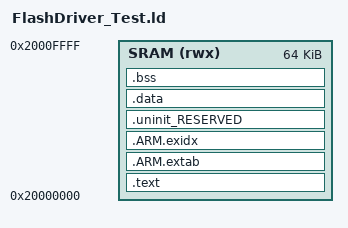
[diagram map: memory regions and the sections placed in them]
/*
 * Linker script for NXP iMXRT SPIFI Flash Driver (Messaged)
*/

__stack_size = 128;								/* stack size */
__cache_size = (16 * 1024);			/* flash image buffer size */
	
MEMORY
{
	  SRAM (rwx) : ORIGIN = 0x20000000, LENGTH = (64 * 1024)
}


__top_SRAM = 0x20000000 + (64 * 1024);

 
GROUP(libcr_semihost.a libcr_c.a libcr_eabihelpers.a)


SEARCH_DIR(..)

ENTRY(ResetISR)

SECTIONS
{

	/* MAIN TEXT SECTION */	
	.text : ALIGN(4)
	{
		FILL(0xff)
		KEEP(*(.isr_vector))
		
		/* Global Section Table */
		. = ALIGN(4) ;
		__section_table_start = .;
		__data_section_table = .;
		LONG(LOADADDR(.data));
		LONG(    ADDR(.data)) ;
		LONG(  SIZEOF(.data));
		__data_section_table_end = .;
		__bss_section_table = .;
		LONG(    ADDR(.bss));
		LONG(  SIZEOF(.bss));
		__bss_section_table_end = .;
		__section_table_end = . ;
		/* End of Global Section Table */
		

		*(.after_vectors*)
		
		*(.text*)
		*(.rodata .rodata.*)
		. = ALIGN(4);
		
	} > SRAM

	/*
	 * for exception handling/unwind - some Newlib functions (in common
	 * with C++ and STDC++) use this.
	 */
	.ARM.extab : ALIGN(4)
	{
		*(.ARM.extab* .gnu.linkonce.armextab.*)
	} > SRAM
	__exidx_start = .;
	
	.ARM.exidx : ALIGN(4)
	{
		*(.ARM.exidx* .gnu.linkonce.armexidx.*)
	} > SRAM
	__exidx_end = .;
	
	_etext = .;
		
	
	/* MAIN DATA SECTION */

	.uninit_RESERVED : ALIGN(4)
	{
		KEEP(*(.bss.$RESERVED*))
	} > SRAM

	.data : ALIGN(4)
	{
		FILL(0xff)
		_data = .;
		*(vtable)
		*(.data*)
		. = ALIGN(4) ;
		_edata = .;
	} > SRAM


	/* MAIN BSS SECTION */
	.bss : ALIGN(4)
	{
		_bss = .;
		*(.bss*)
		*(COMMON)
		. = ALIGN(4) ;
		_ebss = .;
		PROVIDE(end = .);
	} > SRAM
	
	PROVIDE(_pvHeapStart = .);
	PROVIDE(_vStackTop = __top_SRAM - 0);
}
